# f28003x_memory_error_regs register map
Vendor: Texas Instruments
Peripheral module from a debugger description file (folder C2000).
Address unit: 16 bits
Registers are 32-bit, read-only, no defined reset value unless marked. A register's access mark holds for its fields unless they carry their own. Offsets are as the file gives them; lines under a group give offsets from that group; [hi:lo] are bit positions; {n}, {i} and the like mark numbered series; 'fields as' and 'values as' point back to an identical list; <NAME> marks a mode.

## MEMORY_ERROR_REGS — MEMORY ERROR Registers
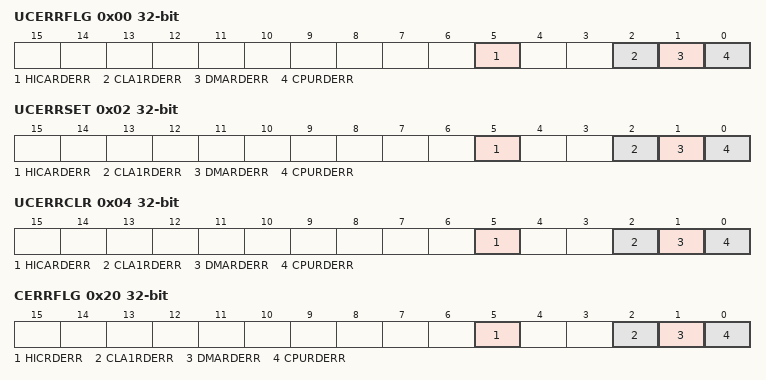
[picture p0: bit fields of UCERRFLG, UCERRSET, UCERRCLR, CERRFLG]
0x00 UCERRFLG — Uncorrectable Error Flag Register
  [5] HICARDERR — HICA Uncorrectable Read Error Flag
  [2] CLA1RDERR — CLA1 Uncorrectable Read Error Flag
  [1] DMARDERR — DMA Uncorrectable Read Error Flag
  [0] CPURDERR — CPU Uncorrectable Read Error Flag
0x02 UCERRSET rw — Uncorrectable Error Flag Set Register
  [5] HICARDERR — HICA Uncorrectable Read Error Flag Set
  [2] CLA1RDERR — CLA1 Uncorrectable Read Error Flag Set
  [1] DMARDERR — DMA Uncorrectable Read Error Flag Set
  [0] CPURDERR — CPU Uncorrectable Read Error Flag Set
0x04 UCERRCLR rw — Uncorrectable Error Flag Clear Register
  [5] HICARDERR — HICA Uncorrectable Read Error Flag Clear
  [2] CLA1RDERR — CLA1 Uncorrectable Read Error Flag Clear
  [1] DMARDERR — DMA Uncorrectable Read Error Flag Clear
  [0] CPURDERR — CPU Uncorrectable Read Error Flag Clear
0x06 UCCPUREADDR — Uncorrectable CPU Read Error Address
  [31:0] UCCPUREADDR — Uncorrectable CPU read/fetch access address register.
0x08 UCDMAREADDR — Uncorrectable DMA Read Error Address
  [31:0] UCDMAREADDR — Uncorrectable DMA read access address register.
0x0A UCCLA1READDR — Uncorrectable CLA1 Read Error Address
  [31:0] UCCLA1READDR — Uncorrectable CLA1 read/fetch access address register.
0x10 UCHICAREADDR — Uncorrectable HICA Read Error Address
  [31:0] UCHICAREADDR — Uncorrectable HICA read/fetch access address register.
0x20 CERRFLG — Correctable Error Flag Register
  [5] HICRDERR — HIC Correctable Read Error Flag
  [2] CLA1RDERR — CLA1 Correctable Read Error Flag
  [1] DMARDERR — DMA Correctable Read Error Flag
  [0] CPURDERR — CPU Correctable Read Error Flag
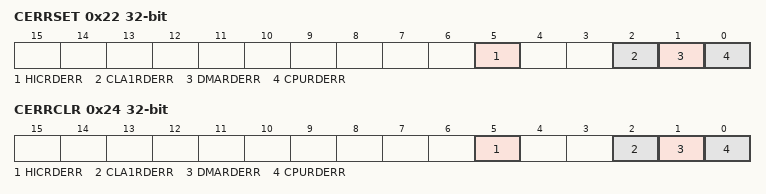
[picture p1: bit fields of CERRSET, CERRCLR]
0x22 CERRSET rw — Correctable Error Flag Set Register
  [5] HICRDERR — HIC Correctable Read Error Flag Set
  [2] CLA1RDERR — CLA1 Correctable Read Error Flag Set
  [1] DMARDERR — DMA Correctable Read Error Flag Set
  [0] CPURDERR — CPU Correctable Read Error Flag Set
0x24 CERRCLR rw — Correctable Error Flag Clear Register
  [5] HICRDERR — HIC Correctable Read Error Flag Clear
  [2] CLA1RDERR — CLA1 Correctable Read Error Flag Clear
  [1] DMARDERR — DMA Correctable Read Error Flag Clear
  [0] CPURDERR — CPU Correctable Read Error Flag Clear
0x26 CCPUREADDR — Correctable CPU Read Error Address
  [31:0] CCPUREADDR — Correctable CPU read/fetch access address register.
0x28 CDMAREADDR — Correctable DMA Read Error Address
  [31:0] CDMAREADDR — Correctable DMA read access address register.
0x2A CCLA1READDR — Correctable CLA1 Read Error Address
  [31:0] CCLA1READDR — Correctable CLA1 read/fetch access address register.
0x2E CERRCNT — Correctable Error Count Register
  [31:0] CERRCNT — Correctable error count.
0x30 CERRTHRES rw — Correctable Error Threshold Value Register
  [15:0] CERRTHRES — Correctable error threshold.
0x32 CEINTFLG — Correctable Error Interrupt Flag Status Register
  [0] CEINTFLAG — Total corrected error count exceeded threshold flag.
0x34 CEINTCLR rw — Correctable Error Interrupt Flag Clear Register
  [0] CEINTCLR — CPU Corrected Error Threshold Exceeded Error Clear.
0x36 CEINTSET rw — Correctable Error Interrupt Flag Set Register
  [0] CEINTSET — Total corrected error count exceeded flag set.
0x38 CEINTEN rw — Correctable Error Interrupt Enable Register
  [0] CEINTEN — CPU/DMA Correctable Error Interrupt Enable.
0x3A CHICREADDR — Correctable HIC Read Error Address
  [31:0] CHICREADDR — Correctable HIC read/fetch access address register.
